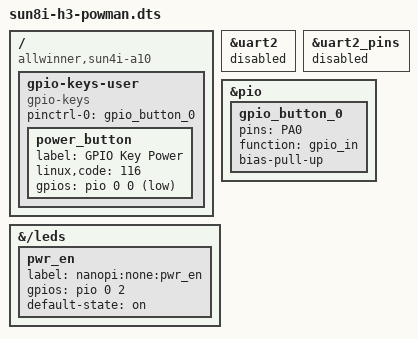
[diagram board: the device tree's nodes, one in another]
/dts-v1/;
/plugin/;

/ {
	compatible = "allwinner,sun4i-a10", "allwinner,sun7i-a20", "allwinner,sun8i-h3", "allwinner,sun50i-a64", "allwinner,sun50i-h5";

	/*
	 * Disable PA0 pin from UART2
	 */

    fragment@0 {
		target = <&uart2>;
		__overlay__ {
			status = "disabled";
		};
    };
    fragment@1 {
		target = <&uart2_pins>;
		__overlay__ {
			status = "disabled";
		};
    };


	/*
	 * This fragment is needed only for the internal pull-up activation,
	 * external pull-up resistor is highly recommended if using long wires
	 */
	fragment@2 {
		target = <&pio>;
		__overlay__ {
			gpio_button_0: gpio_button_0 {
				pins = "PA0";
				function = "gpio_in";
				bias-pull-up;
			};
		};
	};

	fragment@3 {
		target-path = "/";
		__overlay__ {
			gpio-keys-user {
				/*
				 * Use "gpio-keys" for EINT capable pins, "gpio-keys-polled" for other pins
				 * add "poll-interval" property if using "gpio-keys-polled"
				 */
				compatible = "gpio-keys";
				pinctrl-names = "default";
				pinctrl-0 = <&gpio_button_0>;

				power_button {
					label = "GPIO Key Power";
					linux,code = <116>; /* KEY_POWER, see include/uapi/linux/input-event-codes.h */
					gpios = <&pio 0 0 1>; /* PA2 GPIO_ACTIVE_LOW */
				};
			};
		};
	};
	
    fragment@4 {
	target-path = "/leds";
		__overlay__ {
			pwr_en {
				label = "nanopi:none:pwr_en";
				gpios = <&pio 0 2 0>;
				default-state = "on";
			};
		};
    };
	
};
